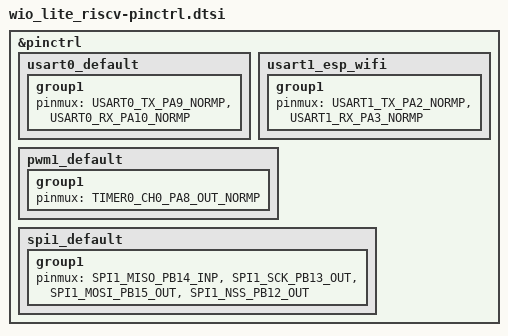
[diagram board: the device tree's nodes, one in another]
/*
 * Copyright (c) 2023, Tada Hiroki
 * SPDX-License-Identifier: Apache-2.0
 */

#include <dt-bindings/pinctrl/gd32vf103c(b-8)xx-pinctrl.h>

&pinctrl {
	usart0_default: usart0_default {
		group1 {
			pinmux = <USART0_TX_PA9_NORMP>, <USART0_RX_PA10_NORMP>;
		};
	};

	usart1_esp_wifi: usart1_esp_wifi {
		group1 {
			pinmux = <USART1_TX_PA2_NORMP>, <USART1_RX_PA3_NORMP>;
		};
	};

	pwm1_default: pwm1_default {
		group1 {
			pinmux = <TIMER0_CH0_PA8_OUT_NORMP>;
		};
	};

	spi1_default: spi1_default {
		group1 {
			pinmux = <SPI1_MISO_PB14_INP>, <SPI1_SCK_PB13_OUT>,
				 <SPI1_MOSI_PB15_OUT>, <SPI1_NSS_PB12_OUT>;
		};
	};
};
